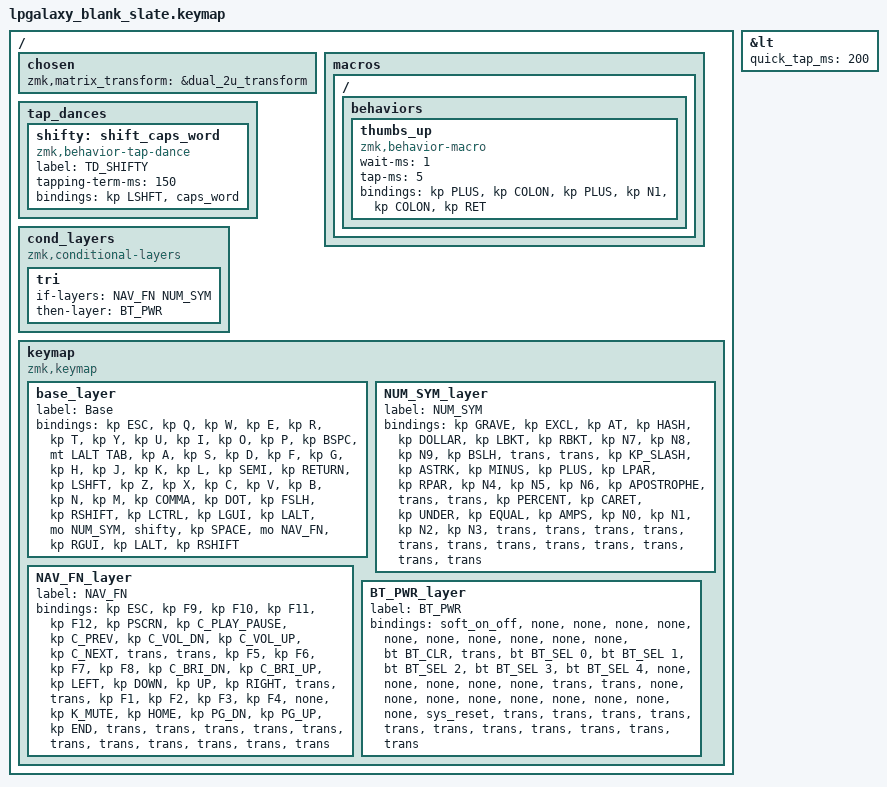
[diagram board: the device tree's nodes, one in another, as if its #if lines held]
/*
 * Copyright (c) 2022 Pete Johanson
 *
 * SPDX-License-Identifier: MIT
 */

#include <behaviors.dtsi>
#include <dt-bindings/zmk/keys.h>
#include <dt-bindings/zmk/bt.h>
#include <dt-bindings/zmk/outputs.h>

#define QWERTY_BASE 1

#define TBLE_ORTHO   1
// #define TBLE_MIT     1
// #define TBLE_DUAL_2U 1

#define NUM_SYM 1
#define NAV_FN 2
#define BT_PWR 3

// Using layer taps on thumbs, having quick tap as well helps w/ repeating space/backspace
&lt { quick_tap_ms = <200>; };

#define BT(n) BT_SEL n

/ {
    chosen {
       zmk,matrix_transform =
#ifdef TBLE_DUAL_2U
                       &dual_2u_transform;
#elif defined(TBLE_MIT)
                       &mit_transform;
#else
                       &ortho_transform;
#endif
    };

    macros {
      ZMK_MACRO(thumbs_up,
		wait-ms = <1>;
		tap-ms = <5>;
                bindings = <&kp PLUS &kp COLON &kp PLUS &kp N1 &kp COLON &kp RET>;
		)
    };
    
    tap_dances {
    	shifty: shift_caps_word {
		compatible = "zmk,behavior-tap-dance";
		label = "TD_SHIFTY";
		#binding-cells = <0>;
		tapping-term-ms = <150>;
		bindings = <&kp LSHFT>, <&caps_word>;
	};
    };

// Conditional layer only when we have less thumb keys
#ifdef TBLE_DUAL_2U
    cond_layers {
        compatible = "zmk,conditional-layers";
	tri {
	    if-layers = <NAV_FN NUM_SYM>;
	    then-layer = <BT_PWR>;
        };
    };
#endif

    keymap {
        compatible = "zmk,keymap";

        base_layer {
            label = "Base";
            bindings = <
#ifdef QWERTY_BASE
 &kp ESC        &kp Q      &kp W      &kp E       &kp R          &kp T          &kp Y            &kp U          &kp I       &kp O      &kp P         &kp BSPC
 &mt LALT TAB   &kp A      &kp S      &kp D       &kp F          &kp G          &kp H            &kp J          &kp K       &kp L      &kp SEMI      &kp RETURN
 &kp LSHFT      &kp Z      &kp X      &kp C       &kp V          &kp B          &kp N            &kp M          &kp COMMA   &kp DOT    &kp FSLH      &kp RSHIFT
#else
 &kp ESC        &kp Q      &kp W      &kp F       &kp P          &kp B          &kp J            &kp L          &kp U       &kp Y      &kp QUOT      &kp BSPC
 &mt LALT TAB   &kp A      &kp R      &kp S       &kp T          &kp G          &kp M            &kp N          &kp E       &kp I      &kp O         &kp RETURN
 &kp LSHFT      &kp Z      &kp X      &kp C       &kp D          &kp V          &kp K            &kp H          &kp COMMA   &kp DOT    &kp SEMI      &kp RSHIFT
#endif
#ifdef TBLE_DUAL_2U
 &kp LCTRL  &kp LGUI   &kp LALT   &mo NUM_SYM         &shifty                        &kp SPACE                &mo NAV_FN   &kp RGUI   &kp LALT      &kp RSHIFT
#elif defined(TBLE_MIT)
 &kp LCTRL  &mo BT_PWR   &kp LALT  &kp LGUI    &mo NUM_SYM          &kp SPACE                   &mo NAV_FN      &kp RGUI    &kp RALT     &kp CAPS      &kp RCTRL
#else
 &kp LCTRL  &mo BT_PWR   &kp LALT  &kp LGUI    &mo NUM_SYM      &kp SPACE      &mt LSHIFT SPACE          &mo NAV_FN      &kp RGUI    &kp RALT     &kp CAPS      &kp RCTRL
#endif
            >;
        };

        NUM_SYM_layer {
            label = "NUM_SYM";
            bindings = <
&kp GRAVE   &kp EXCL         &kp AT         &kp HASH       &kp DOLLAR        &kp LBKT       &kp RBKT     &kp N7       &kp N8    &kp N9     &kp BSLH         &trans
&trans      &kp KP_SLASH     &kp ASTRK      &kp MINUS      &kp PLUS          &kp LPAR       &kp RPAR     &kp N4       &kp N5    &kp N6     &kp APOSTROPHE   &trans
&trans      &kp PERCENT      &kp CARET      &kp UNDER      &kp EQUAL         &kp AMPS       &kp N0       &kp N1       &kp N2    &kp N3     &trans           &trans
#ifdef TBLE_DUAL_2U
&trans  &trans        &trans     &trans              &trans                    &trans       &trans         &trans &trans &trans
#elif defined(TBLE_MIT)
&trans  &trans        &trans     &trans      &trans                &trans             &trans      &trans   &trans &trans &trans
#else
&trans  &trans        &trans     &trans      &trans          &trans       &trans    &trans  &trans         &trans &trans &trans
#endif
            >;
        };

        NAV_FN_layer {
            label = "NAV_FN";
            bindings = <
&kp ESC    &kp F9   &kp F10     &kp F11     &kp F12   &kp PSCRN     &kp C_PLAY_PAUSE    &kp C_PREV      &kp C_VOL_DN        &kp C_VOL_UP    &kp C_NEXT      &trans
&trans     &kp F5   &kp F6      &kp F7      &kp F8    &kp C_BRI_DN  &kp C_BRI_UP        &kp LEFT        &kp DOWN            &kp UP          &kp RIGHT       &trans
&trans     &kp F1   &kp F2      &kp F3      &kp F4    &none         &kp K_MUTE          &kp HOME        &kp PG_DN           &kp PG_UP       &kp END         &trans
#ifdef TBLE_DUAL_2U
&trans  &trans       &trans     &trans              &trans                 &trans            &trans         &trans &trans &trans
#elif defined(TBLE_MIT)
&trans  &trans       &trans     &trans      &trans           &trans            &trans        &trans      &trans &trans &trans
#else
&trans     &trans   &trans      &trans      &trans    &trans        &trans              &trans          &trans              &trans          &trans          &trans
#endif
            >;
        };

        BT_PWR_layer {
            label = "BT_PWR";
            bindings = <
&soft_on_off  &none            &none           &none           &none           &none           &none      &none    &none       &none       &none           &bt BT_CLR
&trans     &bt BT_SEL 0     &bt BT_SEL 1    &bt BT_SEL 2    &bt BT_SEL 3    &bt BT_SEL 4    &none      &none    &none       &none       &none           &trans
&trans     &none            &none           &none           &none           &none           &none      &none    &none       &none       &sys_reset      &trans
#ifdef TBLE_DUAL_2U
&trans &trans        &trans     &trans                &trans                    &trans       &trans         &trans &trans &trans
#elif defined(TBLE_MIT)
&trans &trans        &trans     &trans        &trans                &trans             &trans      &trans   &trans &trans &trans
#else
&trans &trans        &trans     &trans        &trans          &trans       &trans    &trans  &trans         &trans &trans &trans
#endif
            >;
        };


    };
};

